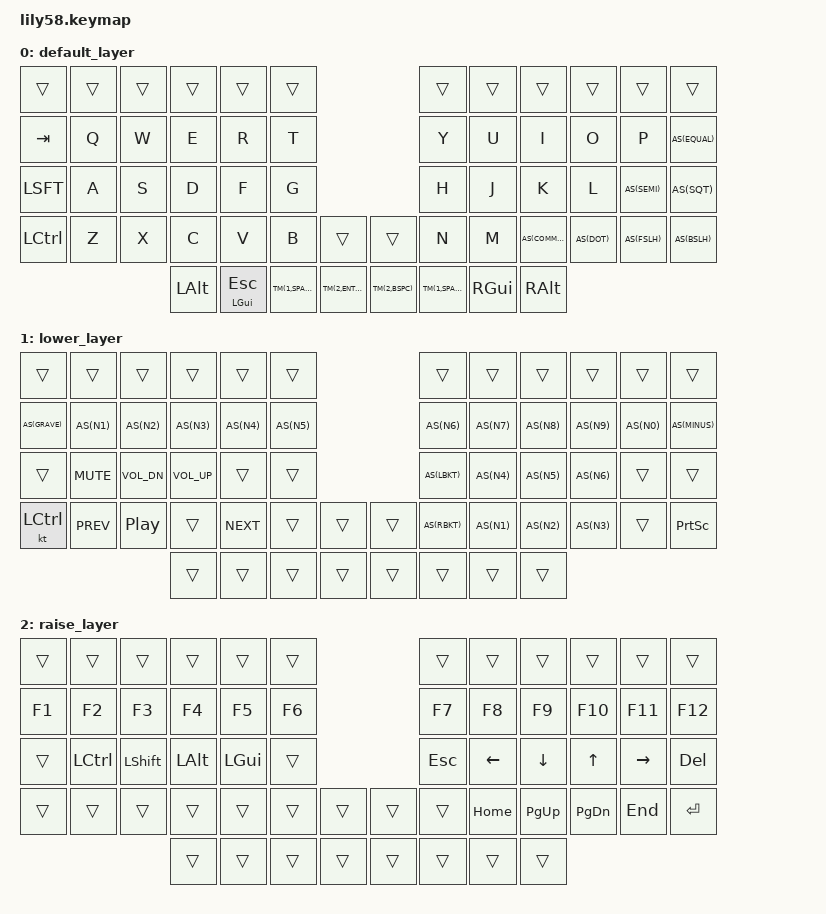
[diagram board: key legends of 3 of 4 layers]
/*
 * Copyright (c) 2022 The ZMK Contributors
 *
 * SPDX-License-Identifier: MIT
 */

#include <behaviors.dtsi>
#include <dt-bindings/zmk/keys.h>
#include <dt-bindings/zmk/bt.h>
#include <dt-bindings/zmk/ext_power.h>
#include <dt-bindings/zmk/outputs.h>

#define AS(keycode) &as LS(keycode) keycode
#define TM(layer, keycode) &tm layer keycode
#define SCW(mod) &scw mod 0

/ {
        combos {
            compatible = "zmk,combos";
            combo_esc {
                timeout-ms = <100>;
                key-positions = <13 14>;
                bindings = <&kp ESC>;
            };
        };
        behaviors {
            as: auto_shift {
                compatible = "zmk,behavior-hold-tap";
                label = "AUTO_SHIFT";
                #binding-cells = <2>;
                tapping-term-ms = <200>;
                quick-tap-ms = <195>;
                flavor = "tap-preferred";
                bindings = <&kp>, <&kp>;
            };
            tm: thumb_mod {
                compatible = "zmk,behavior-hold-tap";
                label = "THUMB_LAYER_TAB";
                #binding-cells = <2>;
                flavor = "tap-preferred";
                tapping-term-ms = <200>;
                quick-tap-ms = <195>;
                bindings = <&mo>, <&kp>;
            };
            scw: shift_caps_word {
                compatible = "zmk,behavior-hold-tap";
                label = "SHIFT_CAPS_WORD";
                #binding-cells = <2>;
                tapping-term-ms = <200>;
                quick-tap-ms = <195>;
                flavor = "hold-preferred";
                bindings = <&kp>, <&caps_word>;
            };
            conditional_layers {
                compatible = "zmk,conditional-layers";
                tri_layer {
                    if-layers = <1 2>;
                    then-layer = <3>;
                };
            };
        };

    keymap {
        compatible = "zmk,keymap";

        default_layer {
            bindings = <
&trans    &trans  &trans  &trans    &trans        &trans                                 &trans        &trans    &trans    &trans  &trans    &trans      
&kp TAB   &kp Q   &kp W   &kp E     &kp R         &kp T                                  &kp Y         &kp U     &kp I     &kp O   &kp P     AS(EQUAL)
&kp LSFT  &kp A   &kp S   &kp D     &kp F         &kp G                                  &kp H         &kp J     &kp K     &kp L   AS(SEMI)  AS(SQT)
&kp LCTRL &kp Z   &kp X   &kp C     &kp V         &kp B       &trans       &trans        &kp N         &kp M     AS(COMMA) AS(DOT) AS(FSLH)  AS(BSLH)
                          &kp LALT  &mt LGUI ESC  TM(1,SPACE) TM(2,ENTER)  TM(2,BSPC)    TM(1,SPACE)   &kp RGUI  &kp RALT
            >;
        };

        lower_layer {
            bindings = <
&trans     &trans           &trans            &trans            &trans       &trans                          &trans          &trans          &trans          &trans       &trans        &trans
AS(GRAVE)  AS(N1)           AS(N2)            AS(N3)            AS(N4)       AS(N5)                          AS(N6)          AS(N7)          AS(N8)          AS(N9)       AS(N0)        AS(MINUS)
&trans     &kp C_MUTE       &kp C_VOL_DN      &kp C_VOL_UP      &trans       &trans                          AS(LBKT)        AS(N4)          AS(N5)          AS(N6)       &trans        &trans   
&kt LCTRL  &kp C_PREV       &kp C_PLAY_PAUSE  &trans            &kp C_NEXT   &trans      &trans     &trans   AS(RBKT)        AS(N1)          AS(N2)          AS(N3)       &trans        &kp PSCRN 
                                              &trans            &trans       &trans      &trans     &trans   &trans          &trans          &trans
            >;
        };

        raise_layer {
            bindings = <
&trans    &trans    &trans    &trans    &trans    &trans                    &trans      &trans       &trans      &trans       &trans        &trans      
&kp F1    &kp F2    &kp F3    &kp F4    &kp F5    &kp F6                    &kp F7      &kp F8       &kp F9      &kp F10      &kp F11       &kp F12
&trans    &kp LCTRL &kp LSHFT &kp LALT  &kp LGUI  &trans                    &kp ESC     &kp LEFT     &kp DOWN    &kp UP       &kp RIGHT     &kp DEL
&trans    &trans    &trans    &trans    &trans    &trans  &trans   &trans   &trans      &kp HOME     &kp PG_UP   &kp PG_DN    &kp END       &kp ENTER
                              &trans    &trans    &trans  &trans   &trans   &trans      &trans       &trans
            >;
        };

        adjust_layer {
            bindings = <
&trans     &trans           &trans            &trans            &trans       &trans                          &trans          &trans          &trans          &trans       &trans        &trans      
&bt BT_CLR &bt BT_SEL 0     &bt BT_SEL 1      &bt BT_SEL 2      &bt BT_SEL 3 &bt BT_SEL 4                    &out OUT_BLE    &out OUT_USB    &trans          &trans       &trans        &trans
&trans     &trans           &trans            &trans            &trans       &trans                          &trans          &trans          &trans          &trans       &trans        &trans      
&bt EP_TOG &trans           &trans            &trans            &trans       &trans      &trans     &trans   &trans          &trans          &trans          &trans       &trans        &trans      
            >;
        };
    };
};
